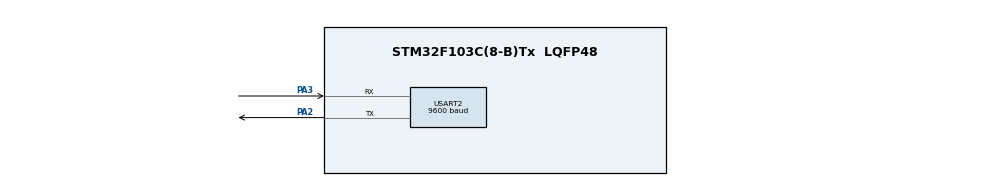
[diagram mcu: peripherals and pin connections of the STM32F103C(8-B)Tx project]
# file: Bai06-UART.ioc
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Mcu.Family=STM32F1
Mcu.Name=STM32F103C(8-B)Tx
Mcu.Package=LQFP48
NVIC.PriorityGroup=NVIC_PRIORITYGROUP_4
NVIC.USART2_IRQn=true\:0\:0\:false\:false\:true
PA13.Mode=Serial_Wire
PA13.Signal=SYS_JTMS-SWDIO
PA14.Mode=Serial_Wire
PA14.Signal=SYS_JTCK-SWCLK
PA2.Mode=Asynchronous
PA2.Signal=USART2_TX
PA3.Mode=Asynchronous
PA3.Signal=USART2_RX
PD0-OSC_IN.Mode=HSE-External-Oscillator
PD0-OSC_IN.Signal=RCC_OSC_IN
PD1-OSC_OUT.Mode=HSE-External-Oscillator
PD1-OSC_OUT.Signal=RCC_OSC_OUT
ProjectManager.HeapSize=0x200
ProjectManager.StackSize=0x400
ProjectManager.TargetToolchain=MDK-ARM V5
RCC.APB1Freq_Value=8000000
RCC.APB2Freq_Value=8000000
RCC.SYSCLKSource=RCC_SYSCLKSOURCE_HSE
USART2.BaudRate=9600
USART2.VirtualMode=VM_ASYNC
board=Bai06-UART

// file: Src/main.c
/**
  ******************************************************************************
  * File Name          : main.c
  * Description        : Main program body
  ******************************************************************************
  ** This notice applies to any and all portions of this file
  * that are not between comment pairs USER CODE BEGIN and
  * USER CODE END. Other portions of this file, whether
  * inserted by the user or by software development tools
  * are owned by their respective copyright owners.
  *
  * COPYRIGHT(c) 2017 STMicroelectronics
  *
  * Redistribution and use in source and binary forms, with or without modification,
  * are permitted provided that the following conditions are met:
  *   1. Redistributions of source code must retain the above copyright notice,
  *      this list of conditions and the following disclaimer.
  *   2. Redistributions in binary form must reproduce the above copyright notice,
  *      this list of conditions and the following disclaimer in the documentation
  *      and/or other materials provided with the distribution.
  *   3. Neither the name of STMicroelectronics nor the names of its contributors
  *      may be used to endorse or promote products derived from this software
  *      without specific prior written permission.
  *
  * THIS SOFTWARE IS PROVIDED BY THE COPYRIGHT HOLDERS AND CONTRIBUTORS "AS IS"
  * AND ANY EXPRESS OR IMPLIED WARRANTIES, INCLUDING, BUT NOT LIMITED TO, THE
  * IMPLIED WARRANTIES OF MERCHANTABILITY AND FITNESS FOR A PARTICULAR PURPOSE ARE
  * DISCLAIMED. IN NO EVENT SHALL THE COPYRIGHT HOLDER OR CONTRIBUTORS BE LIABLE
  * FOR ANY DIRECT, INDIRECT, INCIDENTAL, SPECIAL, EXEMPLARY, OR CONSEQUENTIAL
  * DAMAGES (INCLUDING, BUT NOT LIMITED TO, PROCUREMENT OF SUBSTITUTE GOODS OR
  * SERVICES; LOSS OF USE, DATA, OR PROFITS; OR BUSINESS INTERRUPTION) HOWEVER
  * CAUSED AND ON ANY THEORY OF LIABILITY, WHETHER IN CONTRACT, STRICT LIABILITY,
  * OR TORT (INCLUDING NEGLIGENCE OR OTHERWISE) ARISING IN ANY WAY OUT OF THE USE
  * OF THIS SOFTWARE, EVEN IF ADVISED OF THE POSSIBILITY OF SUCH DAMAGE.
  *
  ******************************************************************************
  */
#include "main.h"
#include "stm32f1xx_hal.h"

/* USER CODE BEGIN Includes */

//Hung
#include "stdio.h" //Thu vien chua ham sprintf - chuyen chuoi ky tu thanh mang de hien thi
#include "string.h" //Thu vien xu ly chua ham strlen()

/* USER CODE END Includes */

UART_HandleTypeDef huart2;

/* USER CODE BEGIN PV */
/* Private variables ---------------------------------------------------------*/

//Hung
char buffer[100]; // => Bo dem chua du lieu nhan ve: bo dem trong chip de chua du lieu (gan giong nhu RAM trong PC)
int doDaiChuoi;
unsigned char i = 0;

/* USER CODE END PV */

void SystemClock_Config(void);
static void MX_GPIO_Init(void);
static void MX_USART2_UART_Init(void);

/* USER CODE BEGIN PFP */
/* Private function prototypes -----------------------------------------------*/

/* USER CODE END PFP */

int main(void)
{

  /* MCU Configuration----------------------------------------------------------*/

  /* Reset of all peripherals, Initializes the Flash interface and the Systick. */
  HAL_Init();

  /* Configure the system clock */
  SystemClock_Config();

  /* Initialize all configured peripherals */
  MX_GPIO_Init();
  MX_USART2_UART_Init();

  /* Infinite loop */
  /* USER CODE BEGIN WHILE */
  while (1)
  {

		//Hung
		sprintf(buffer, "%0.4d",i);
		doDaiChuoi = strlen(buffer); //Lay do dai cua chuoi trong mang buffer;
		HAL_UART_Transmit(&huart2, buffer, doDaiChuoi, 1000); //1000 la thoi gian timeout
		// &huart2 la dia chi cua kenh UART2
		// buffer la mang chua cac ky tu can truyen
		// doDaiChuoi la do dai cua mang ky tu can truyen di
		// 1000 la thoi gian truyen, neu qua thi bao loi (mili second)
		HAL_Delay(500);
		i++;

  /* USER CODE END WHILE */

  }

}

/** System Clock Configuration
*/
void SystemClock_Config(void)
{

  RCC_OscInitTypeDef RCC_OscInitStruct;
  RCC_ClkInitTypeDef RCC_ClkInitStruct;

    /**Initializes the CPU, AHB and APB busses clocks
    */
  RCC_OscInitStruct.OscillatorType = RCC_OSCILLATORTYPE_HSE;
  RCC_OscInitStruct.HSEState = RCC_HSE_ON;
  RCC_OscInitStruct.PLL.PLLState = RCC_PLL_NONE;
  if (HAL_RCC_OscConfig(&RCC_OscInitStruct) != HAL_OK)
  {
    _Error_Handler(__FILE__, __LINE__);
  }

    /**Initializes the CPU, AHB and APB busses clocks
    */
  RCC_ClkInitStruct.ClockType = RCC_CLOCKTYPE_HCLK|RCC_CLOCKTYPE_SYSCLK
                              |RCC_CLOCKTYPE_PCLK1|RCC_CLOCKTYPE_PCLK2;
  RCC_ClkInitStruct.SYSCLKSource = RCC_SYSCLKSOURCE_HSE;
  RCC_ClkInitStruct.AHBCLKDivider = RCC_SYSCLK_DIV1;
  RCC_ClkInitStruct.APB1CLKDivider = RCC_HCLK_DIV1;
  RCC_ClkInitStruct.APB2CLKDivider = RCC_HCLK_DIV1;

  if (HAL_RCC_ClockConfig(&RCC_ClkInitStruct, FLASH_LATENCY_0) != HAL_OK)
  {
    _Error_Handler(__FILE__, __LINE__);
  }

    /**Configure the Systick interrupt time
    */
  HAL_SYSTICK_Config(HAL_RCC_GetHCLKFreq()/1000);

    /**Configure the Systick
    */
  HAL_SYSTICK_CLKSourceConfig(SYSTICK_CLKSOURCE_HCLK);

  /* SysTick_IRQn interrupt configuration */
  HAL_NVIC_SetPriority(SysTick_IRQn, 0, 0);
}

/* USART2 init function */
static void MX_USART2_UART_Init(void)
{

  huart2.Instance = USART2;
  huart2.Init.BaudRate = 9600;
  huart2.Init.WordLength = UART_WORDLENGTH_8B;
  huart2.Init.StopBits = UART_STOPBITS_1;
  huart2.Init.Parity = UART_PARITY_NONE;
  huart2.Init.Mode = UART_MODE_TX_RX;
  huart2.Init.HwFlowCtl = UART_HWCONTROL_NONE;
  huart2.Init.OverSampling = UART_OVERSAMPLING_16;
  if (HAL_UART_Init(&huart2) != HAL_OK)
  {
    _Error_Handler(__FILE__, __LINE__);
  }

}

/** Configure pins as
        * Analog
        * Input
        * Output
        * EVENT_OUT
        * EXTI
*/
static void MX_GPIO_Init(void)
{

  /* GPIO Ports Clock Enable */
  __HAL_RCC_GPIOD_CLK_ENABLE();
  __HAL_RCC_GPIOA_CLK_ENABLE();

}

void _Error_Handler(char * file, int line)
{
  while(1)
  {
  }
}

/************************ (C) COPYRIGHT STMicroelectronics *****END OF FILE****/
